# LKS32MC07x register map
Vendor: Linko Ltd.; Series: LKS32MC07x; File version: 1.0
CPU: CM0 r1p0, little endian, MPU, no FPU, 3 interrupt priority bits
Registers are 32-bit, read-write, reset 0x0 unless marked. A register's access mark holds for its fields unless they carry their own. Offsets are from the block's base; [hi:lo] are bit positions; {n}, {i} and the like mark numbered series.

## SYS — SYS registers
Base 0x40000000
0x00 AFE_ADC ro — ADC raw data
  [11:0] ADC_RAW_D — DAC Row Data
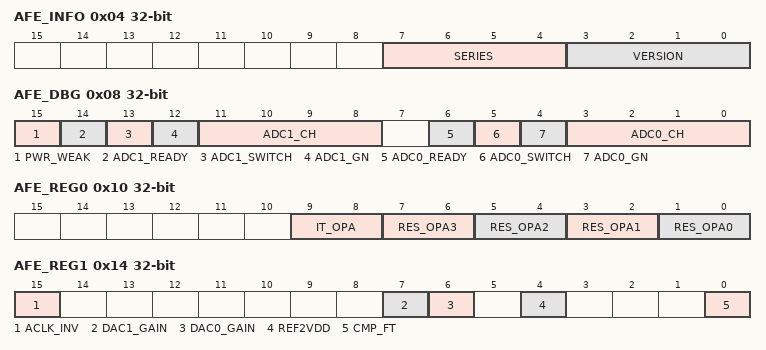
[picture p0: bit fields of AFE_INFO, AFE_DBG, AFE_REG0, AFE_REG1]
0x04 AFE_INFO ro — Chip Version Information
  [7:4] SERIES — Chip Series Information(0x7)
  [3:0] VERSION — Chip Version Information
0x08 AFE_DBG ro — AFE Debug Register
  [15] PWR_WEAK — Power Supply Voltage is lower then Power Mnitor Threshold
  [14] ADC1_READY — ADC1 Data READY Signal from Analog
  [13] ADC1_SWITCH — ADC1 Channel SWITCH Signal from Analog
  [12] ADC1_GN — ADC1 Gain Selection from Digital
  [11:8] ADC1_CH — ADC1 Channel Selection from Digital
  [6] ADC0_READY — ADC0 Data READY Signal from Analog
  [5] ADC0_SWITCH — ADC0 Channel SWITCH Signal from Analog
  [4] ADC0_GN — ADC0 Gain Selection from Digital
  [3:0] ADC0_CH — ADC0 Channel Selection from Digital
0x10 AFE_REG0 — Analog reg0
  [9:8] IT_OPA — OPA bias select
    0=1P0 (1 times); 1=1P2 (1.2 times); 2=1P5 (1.5 times); 3=2P0 (2.0 times)
  [2n+1:2n] RES_OPA{n} (n=0..3) — OPA{n} feedback resistor
    0=320k_10k; 1=160k_10k; 2=80k_10k; 3=40k_10k
0x14 AFE_REG1 — Analog reg1
  [15] ACLK_INV — ADC Clock Inverted
    0=N (Normal); 1=R (Inverted)
  [7] DAC1_GAIN
    0=4P85V (4.85V Full Scale); 1=1P2V (1.2V Full Scale)
  [6] DAC0_GAIN
    0=4P85V (4.85V Full Scale); 1=1P2V (1.2V Full Scale)
  [4] REF2VDD — Use external ADC ref
    0=INTERNAL (Use Interl REF); 1=EXTERNAL (Use External Power)
  [0] CMP_FT — Comparator fast mode
    0=DISABLED (Comparator fast mode disabled); 1=ENABLED (CMP Compare time less then 30ns)
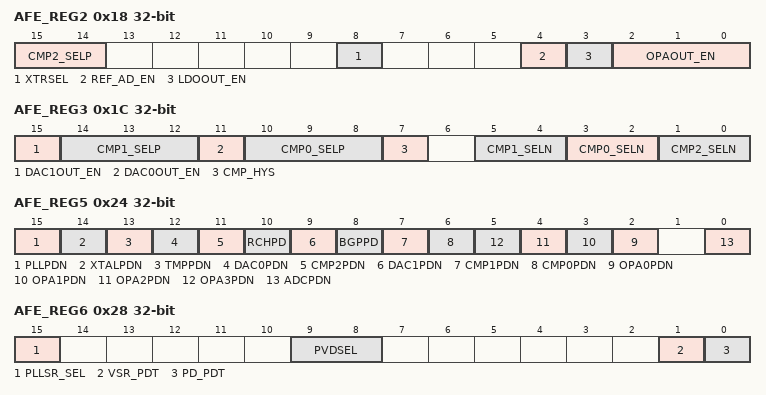
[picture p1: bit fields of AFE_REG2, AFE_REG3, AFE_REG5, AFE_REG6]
0x18 AFE_REG2 — Analog reg2
  [15:14] CMP2_SELP — Comparator 2 positive input select
    0=CMP2_IP0; 1=CMP2_IP1; 2=OPA2_OUT; 3=OPA3_OUT
  [8] XTRSEL — crystal oscillator resistor select
  [4] REF_AD_EN — DAC Reference Output to P2[7]
  [3] LDOOUT_EN — LDO15 Output to P2[7]
  [2:0] OPAOUT_EN — OPA output enable
    0=None (No output); {v}=OPA{v-1} (OPA{v-1} output to P2[7]) (v=1..4)
0x1C AFE_REG3 — Analog reg3
  [15] DAC1OUT_EN — DAC1 output enable
    0=DISABLED (DAC1 output disabled); 1=ENABLED (DAC1 output to P0[0])
  [14:12] CMP1_SELP — Comparator 1 positive input select
    0=CMP1_IP0; 1=OPA3_IP; 2=OPA2_OUT; 3=OPA3_OUT; 4=CMP1_IP1; 5=CMP1_IP2; 6=CMP1_IP3; 7=DAC0 (DAC0 output)
  [11] DAC0OUT_EN — DAC0 output enable
    0=DISABLED (DAC0 output disabled); 1=ENABLED (DAC0 output to P0[0])
  [10:8] CMP0_SELP — Comparator 0 positive input select
    0=CMP0_IP0; 1=OPA0_IP; 2=OPA0_OUT; 3=OPA1_OUT; {v}=CMP0_IP{v-3} (v=4..7)
  [7] CMP_HYS — Comparator hystersis select
    0=20mV; 1=0mV
  [5:4] CMP1_SELN — Comparator 1 negative input select
    0=CMP1_IN; 1=REF; 2=DAC0OUT; 3=BEMF1_MID
  [3:2] CMP0_SELN — Comparator 0 negative input select
    0=CMP0_IN; 1=REF; 2=DAC0OUT; 3=BEMF0_MID
  [1:0] CMP2_SELN — Comparator 2 negative input select
    0=CMP2_IN; 1=REF; 2=DAC0OUT; 3=DAC1OUT
0x20 AFE_REG4 — Analog reg4
0x24 AFE_REG5 — Analog reg5
  [15] PLLPDN — PLL power down
    0=OFF (OFF(Default)); 1=ON
  [14] XTALPDN — Xtal power down
    0=OFF (OFF(Default)); 1=ON
  [13] TMPPDN — Temp sensor power down
    0=OFF (OFF(Default)); 1=ON
  [12] DAC0PDN — DAC0 power down
    0=OFF (OFF(Default)); 1=ON
  [11] CMP2PDN — CMP2 power down
    0=OFF (OFF(Default)); 1=ON
  [10] RCHPD — RC power down
    0=ON (ON(Default)); 1=OFF
  [9] DAC1PDN — DAC1 power down
    0=OFF (OFF(Default)); 1=ON
  [8] BGPPD — Bandgap power down
    0=ON (ON(Default)); 1=OFF
  [7] CMP1PDN — Comparator 1 power down
    0=OFF (OFF(Default)); 1=ON
  [6] CMP0PDN — Comparator 0 power down
    0=OFF (OFF(Default)); 1=ON
  [n+2] OPA{n}PDN (n=0..3) — OPA {n} power down
    0=OFF (OFF(Default)); 1=ON
  [0] ADCPDN — ADC power down
    0=OFF (OFF(Default)); 1=ON
0x28 AFE_REG6 — Analog reg6
  [15] PLLSR_SEL — PLL clock source select
    0=RCH (Use RCH as PLL clock source); 1=XTAL (Use external Xtal as PLL clock source)
  [9:8] PVDSEL — Power down threshold
    0=4P0; 1=3P75; 2=3P5; 3=3P25
  [1] VSR_PDT — Power down reference select
    0=1P3 (Use 1.3V as power down reference); 1=DACOUT (Use DAC output as power down reference)
  [0] PD_PDT — Power down disable
    0=ENABLED (Power down circuit is enabled); 1=DISABLED (Power down circuit is disabled)
0x2C AFE_REG7 — Analog reg7
  [4] ADCLKSEL — ADC clock select
    0=48MHz; 1=24MHz
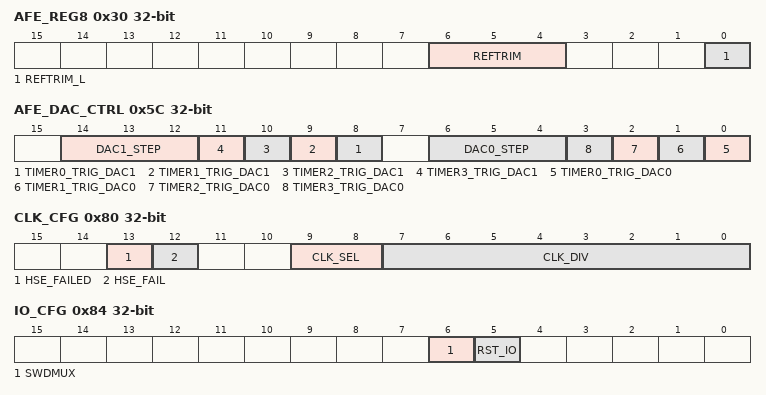
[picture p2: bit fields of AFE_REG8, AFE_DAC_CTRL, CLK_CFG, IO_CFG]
0x30 AFE_REG8 — Analog reg8
  [6:4] REFTRIM — Bandgap output voltage fine tune
    0=0mV; 1=13P5mV (13.5mV); 2=27mV; 3=40P5mV (40.5mV); 4=N54mV (-54mV); 5=N40P5mV (-40.5mV); 6=N27mV (-27mV); 7=N13P5mV (-13.5mV)
  [0] REFTRIM_L — Bandgap output voltage coarse tune(cont)
    0=0mV; 1=7P5mV (7.5mV)
0x34 AFE_REG9 — Analog reg9
0x38 AFE_REGA — Analog regA
  [2:0] LDO15TRIM — LDO15 tune
    3=0P12 (0.12); 2=0P08 (0.08); 1=0P04 (0.04); 0=0; 7=N0P04 (-0.04); 6=N0P08 (-0.08); 4=N0P12 (-0.12)
0x3C AFE_REGB — Analog regB
  [3:0] RCLTRIM — 32kHz RC clock tune
    0=0; 1=0P12 (0.12); 2=0P27 (0.27); 3=0P46 (0.46); 4=N0P13 (-0.13); 8=N0P23 (-0.23); 12=N0P32 (-0.32)
0x40 AFE_REGC — Analog regC
  [5:0] RCHTRIM — 4MHz RC clock tune
    0=0P0000; 1=0P0125 (0.0125); 2=0P0250 (0.025); 3=0P0375 (0.0375); 4=0P0500 (0.05); 5=0P0625 (0.0625); 6=0P0750 (0.075); 7=0P0875 (0.0875); 8=0P1000 (0.1); 9=0P1125 (0.1125); 10=0P1250 (0.125); 11=0P1375 (0.1375); 12=0P1500 (0.15); 13=0P1625 (0.1625); 14=0P1750 (0.175); 15=0P1875 (0.1875); 16=0P2000 (0.2); 17=0P2125 (0.2125); 18=0P2250 (0.225); 19=0P2375 (0.2375); 20=0P2500 (0.25); 21=0P2625 (0.2625); 22=0P2750 (0.275); 23=0P2875 (0.2875); 24=0P3000 (0.3); 25=0P3125 (0.3125); 26=0P3250 (0.325); 27=0P3375 (0.3375); 28=0P3500 (0.35); 29=0P3625 (0.3625); 30=0P3750 (0.375); 31=0P3875 (0.3875); 32=N0P4000 (-0.4); 33=N0P3875 (-0.3875); 34=N0P3750 (-0.375); 35=N0P3625 (-0.3625); 36=N0P3500 (-0.35); 37=N0P3375 (-0.3375); 38=N0P3250 (-0.325); 39=N0P3125 (-0.3125); 40=N0P3000 (-0.3); 41=N0P2875 (-0.2875); 42=N0P2750 (-0.275); 43=N0P2625 (-0.2625); 44=N0P2500 (-0.25); 45=N0P2375 (-0.2375); 46=N0P2250 (-0.225); 47=N0P2125 (-0.2125); 48=N0P2000 (-0.2); 49=N0P1875 (-0.1875); 50=N0P1750 (-0.175); 51=N0P1625 (-0.1625); 52=N0P1500 (-0.15); 53=N0P1375 (-0.1375); 54=N0P1250 (-0.125); 55=N0P1125 (-0.1125); 56=N0P1000 (-0.1); 57=N0P875 (-0.0875); 58=N0P750 (-0.075); 59=N0P625 (-0.0625); 60=N0P500 (-0.05); 61=N0P375 (-0.0375); 62=N0P250 (-0.025); 63=N0P125 (-0.0125)
0x5C AFE_DAC_CTRL — DAC Control Register
  [14:12] DAC1_STEP — SYS_AFE_DAC1 Step Value, 3bit Signed Value(-4~3)
  [n+8] TIMER{n}_TRIG_DAC1 (n=0..3) — TIMER{n} Zero-Crossing Trig DAC1 Step Enabel
  [6:4] DAC0_STEP — SYS_AFE_DAC0 Step Value, 3bit Signed Value(-4~3)
  [n] TIMER{n}_TRIG_DAC0 (n=0..3) — TIMER{n} Zero-Crossing Trig DAC0 Step Enabel
0x60 AFE_DAC0 — DAC0 digital input
  [11:0] DAC_IN — DAC0 digital input value
0x64 AFE_DAC1 — DAC1 digital input
  [11:0] DAC_IN — DAC1 digital input value
0x68 AFE_DAC0_AMC — DAC0 Amplication Calibration
  [9:0] AMC — DAC0 Amplication Calibration Value, 10bit Unsigned Fixed Point Number
0x6C AFE_DAC0_DC — DAC0 DC Offset
  [9:0] DC — DAC0 DC Offset, 10bit Signed Value
0x70 AFE_DAC1_AMC — DAC1 Amplication Calibration
  [9:0] AMC — DAC1 Amplication Calibration Value, 10bit Unsigned Fixed Point Number
0x74 AFE_DAC1_DC — DAC1 DC Offset
  [9:0] DC — DAC1 DC Offset, 10bit Signed Value
0x80 CLK_CFG — Clock configuration
  [13] HSE_FAILED — XTAL have Stopped Event Happened
  [12] HSE_FAIL — XTAL Stopped
  [9:8] CLK_SEL — Select PLL or HRC as system clock
    0=HRC (Use 4MHz HRC as system clock); 1=PLL (Use PLL clock as system clock); 2=LRC (Use LRC clock as system clock); 3=XTAL (Use XTAL clock as system clock)
  [7:0] CLK_DIV — PLL output frequency divider
    1=DIV8 (1/8 frequency div); 17=DIV4 (1/4 frequency div); 85=DIV2 (1/2 frequency div); 255=DIV1 (No div)
0x84 IO_CFG — IO configuration
  [6] SWDMUX — Use SWD as GPIO
    0=DISABLED (P2.14 as SWCLK, P2.15 as SWDIO); 1=ENABLED (P2.14, P2.15 As GPIO)
  [5] RST_IO — Use RSTn as GPIO
    0=DISABLED (As RSTn); 1=ENABLED (As GPIO)
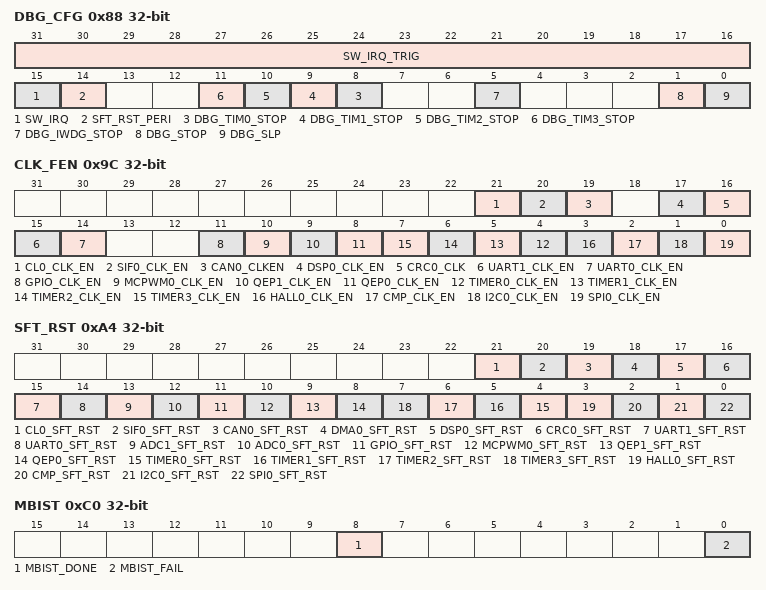
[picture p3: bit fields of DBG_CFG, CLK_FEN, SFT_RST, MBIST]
0x88 DBG_CFG — Debug Configuration
  [31:16] SW_IRQ_TRIG wo — Write 0x5AA5 trig SW_IRQ, and set 1 to SW_IRQ
  [15] SW_IRQ — Software Interrupt Flag, Interrupt No.30, Write 1 Clear
  [14] SFT_RST_PERI — Debug Soft Reset to Reset Peripheral Registers exclude Flash/SYS_AFE
  [n+8] DBG_TIM{n}_STOP (n=0..3) — Stop Timer{n} when CPU halt under Debug Mode
  [5] DBG_IWDG_STOP — Stop IWDG when CPU halt under Debug Mode
  [1] DBG_STOP — Debug STOP Mode
  [0] DBG_SLP — Debug SLEEP Mode
0x90 CLK_DIV0 — I2C Clock division ratio
  [15:0] I2C_CLK_DIV — I2C_CLK=MCLK/(CLK_DIV0+1)
0x98 CLK_DIV2 — UART Clock division ratio
  [15:0] UART_CLK_DIV — UART0/1_CLK=MCLK/(CLK_DIV2+1)
0x9C CLK_FEN — Peripheral clock enable
  [all] fields
    0=DISABLED (Clock is disabled); 1=ENABLED (Clock is enabled)
  [21] CL0_CLK_EN — CL0 module clock enable
  [20] SIF0_CLK_EN — SIF0 module clock enable
  [19] CAN0_CLKEN — CAN0 module clock enable
  [17] DSP0_CLK_EN — DSP0 module clock enable
  [16] CRC0_CLK — CRC0 module clock enable
  [15] UART1_CLK_EN — UART1 module clock enable
  [14] UART0_CLK_EN — UART0 module clock enable
  [11] GPIO_CLK_EN — GPIO module clock enable
  [10] MCPWM0_CLK_EN — MCPWM0 module clock enable
  [9] QEP1_CLK_EN — QEP1 module clock enable
  [8] QEP0_CLK_EN — QEP0 module clock enable
  [n+4] TIMER{n}_CLK_EN (n=0..3) — Timer{n} module clock enable
  [3] HALL0_CLK_EN — HALL0 module clock enable
  [2] CMP_CLK_EN — CMP module clock enable
  [1] I2C0_CLK_EN — I2C0 module clock enable
  [0] SPI0_CLK_EN — SPI0 module clock enable
0xA0 TRIM ro — System trim
  [0] TRIM — After POR, chip in TRIM Mode, chip exit TRIM Mode after Soft RST
    0=NORMAL (NORMAL Mode); 1=TRIM (TRIM Mode)
0xA4 SFT_RST — Peripheral soft reset
  [all] fields
    0=RELEASE (reset release); 1=RESET
  [21] CL0_SFT_RST — CL0 module soft reset
  [20] SIF0_SFT_RST — SIF0 module soft reset
  [19] CAN0_SFT_RST — CAN0 module soft reset
  [18] DMA0_SFT_RST — DMA0 module soft reset
  [17] DSP0_SFT_RST — DSP0 module soft reset
  [16] CRC0_SFT_RST — CRC0 module soft reset
  [15] UART1_SFT_RST — UART1 module soft reset
  [14] UART0_SFT_RST — UART0 module soft reset
  [13] ADC1_SFT_RST — ADC1 module soft reset
  [12] ADC0_SFT_RST — ADC0 module soft reset
  [11] GPIO_SFT_RST — GPIO module soft reset
  [10] MCPWM0_SFT_RST — MCPWM0 module soft reset
  [9] QEP1_SFT_RST — QEP1 module soft reset
  [8] QEP0_SFT_RST — QEP0 module soft reset
  [n+4] TIMER{n}_SFT_RST (n=0..3) — TIMER{n} module soft reset
  [3] HALL0_SFT_RST — HALL0 module soft reset
  [2] CMP_SFT_RST — CMP module soft reset
  [1] I2C0_SFT_RST — I2C module soft reset
  [0] SPI0_SFT_RST — SPI0 module soft reset
0xA8 PROTECT wo — System reg protect
  [15:0] SYS_REG_PROT — Write 0x7A83 to unlock protect
0xC0 MBIST ro — MBIST results
  [8] MBIST_DONE — MBIST Done Signal
    0=UNDONE (MBIST not finished); 1=DONE (MBIST finished)
  [0] MBIST_FAIL — MBIST Result Signal
    0=PASS (MBIST Passed); 1=FAIL (MBIST Failed)
0xFC TEST wo — Test Modes
  [7:0] PSW — Chip Test Register, write different passwd for different test mode
    245=DFT_MODE (DFT test mode); 250=FLASH_MODE (Flash test mode); 252=MBIST_MODE (Memory BIST mode)
